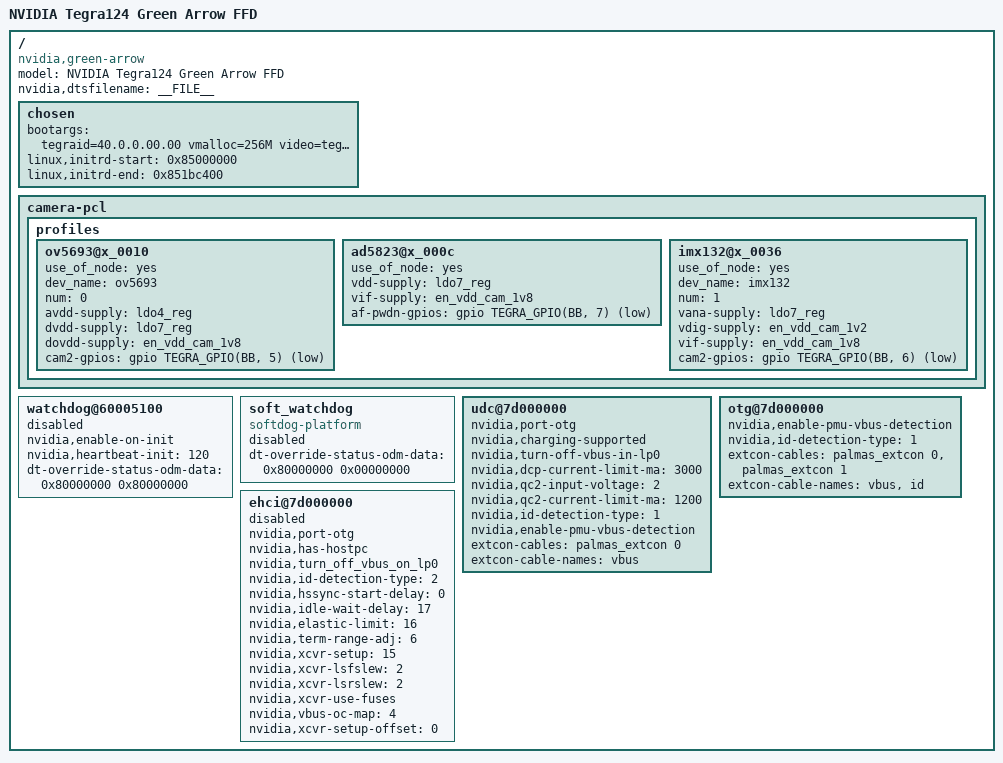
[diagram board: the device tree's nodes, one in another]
/*
 * tegra124-green-arrow-p2267-base-a00.dts: DTS file for Green Arrow base
 *
 * Copyright (c) 2015, NVIDIA CORPORATION.  All rights reserved.
 *
 * This program is free software; you can redistribute it and/or modify
 * it under the terms of the GNU General Public License as published by
 * the Free Software Foundation; either version 2 of the License, or
 * (at your option) any later version.
 *
 * This program is distributed in the hope that it will be useful, but WITHOUT
 * ANY WARRANTY; without even the implied warranty of MERCHANTABILITY or
 * FITNESS FOR A PARTICULAR PURPOSE.  See the GNU General Public License for
 * more details.
 */

/dts-v1/;

#include "tegra124-soc-shield.dtsi"
#include "tegra124-platforms/tegra124-green-arrow-pinmux-p2267-1000-a00.dtsi"
#include "tegra124-platforms/tegra124-green-arrow-p2267-io-common.dtsi"
#include "tegra124-platforms/tegra124-green-arrow-p2267-powertree-e1936-1000-a00.dtsi"
#include "tegra124-platforms/tegra124-green-arrow-touch.dtsi"
#include "tegra124-platforms/tegra124-green-arrow-p2267-sensor-1000-a00.dtsi"
#include "tegra124-platforms/tegra124-green-arrow-keys-p2267-1000-a00.dtsi"
#include "tegra124-platforms/tegra124-green-arrow-dfll.dtsi"
#include "tegra124-platforms/tegra124-green-arrow-camera-p2267-1000-a00.dtsi"
#include "tegra124-platforms/tegra124-green-arrow-usb-devices.dtsi"
#include "tegra124-platforms/tegra124-tn8-hdmi-p1761-1270-a03.dtsi"

/* TODO: comm's dtsi should be included after GPIO dtsi */
#include "tegra124-platforms/tegra124-green-arrow-comms.dtsi"

/ {
	model = "NVIDIA Tegra124 Green Arrow FFD";
	compatible = "nvidia,green-arrow", "nvidia,tegra124";
	nvidia,dtsfilename = __FILE__;
	#address-cells = <2>;
	#size-cells = <2>;

	chosen {
		bootargs = "tegraid=40.0.0.00.00 vmalloc=256M video=tegrafb console=ttyS0,115200n8 earlyprintk";
		linux,initrd-start = <0x85000000>;
		linux,initrd-end = <0x851bc400>;
	};

	camera-pcl {
		profiles {
			ov5693@x_0010 {
				use_of_node = "yes";
				dev_name = "ov5693";
				num = <0>;
				avdd-supply = <&ldo4_reg>;
				dvdd-supply = <&ldo7_reg>;
				dovdd-supply = <&en_vdd_cam_1v8>;
				cam2-gpios = <&gpio TEGRA_GPIO(BB, 5) 1>;
			};
			ad5823@x_000c {
				use_of_node = "yes";
				vdd-supply = <&ldo7_reg>;
				vif-supply = <&en_vdd_cam_1v8>;
				af-pwdn-gpios = <&gpio TEGRA_GPIO(BB, 7) 1>;
			};
			imx132@x_0036 {
				use_of_node = "yes";
				dev_name = "imx132";
				num = <1>;
				vana-supply = <&ldo7_reg>;
				vdig-supply = <&en_vdd_cam_1v2>;
				vif-supply = <&en_vdd_cam_1v8>;
				cam2-gpios = <&gpio TEGRA_GPIO(BB, 6) 1>;
			};
		};
	};

	watchdog@60005100 {
		status = "disabled";
		nvidia,enable-on-init;
		nvidia,heartbeat-init = <120>;
		dt-override-status-odm-data = <0x80000000 0x80000000>;
	};

	soft_watchdog {
		compatible = "softdog-platform";
		status = "disabled";
		dt-override-status-odm-data = <0x80000000 0x00000000>;
	};

	udc@7d000000 {
		nvidia,port-otg;
		nvidia,charging-supported;
		nvidia,turn-off-vbus-in-lp0;
		nvidia,dcp-current-limit-ma = <3000>;
		nvidia,qc2-input-voltage = <2>;
		nvidia,qc2-current-limit-ma = <1200>;
		nvidia,id-detection-type = <1>;
		nvidia,enable-pmu-vbus-detection;
		extcon-cables = <&palmas_extcon 0>;
		extcon-cable-names = "vbus";
		#extcon-cells = <1>;
		status = "okay";
	};

	otg@7d000000 {
		nvidia,enable-pmu-vbus-detection;
		nvidia,id-detection-type = <1>;
		extcon-cables = <&palmas_extcon 0 &palmas_extcon 1>;
		extcon-cable-names = "vbus", "id";
		#extcon-cells = <1>;
		status = "okay";
	};

	ehci@7d000000 {
		nvidia,port-otg;
		nvidia,has-hostpc;
		nvidia,turn_off_vbus_on_lp0;
		nvidia,id-detection-type = <2>;
		nvidia,hssync-start-delay = <0>;
		nvidia,idle-wait-delay = <17>;
		nvidia,elastic-limit = <16>;
		nvidia,term-range-adj = <6>;
		nvidia,xcvr-setup = <15>;
		nvidia,xcvr-lsfslew = <2>;
		nvidia,xcvr-lsrslew = <2>;
		nvidia,xcvr-use-fuses;
		nvidia,vbus-oc-map = <4>;
		nvidia,xcvr-setup-offset = <0>;
		status = "disabled";
	};
};
